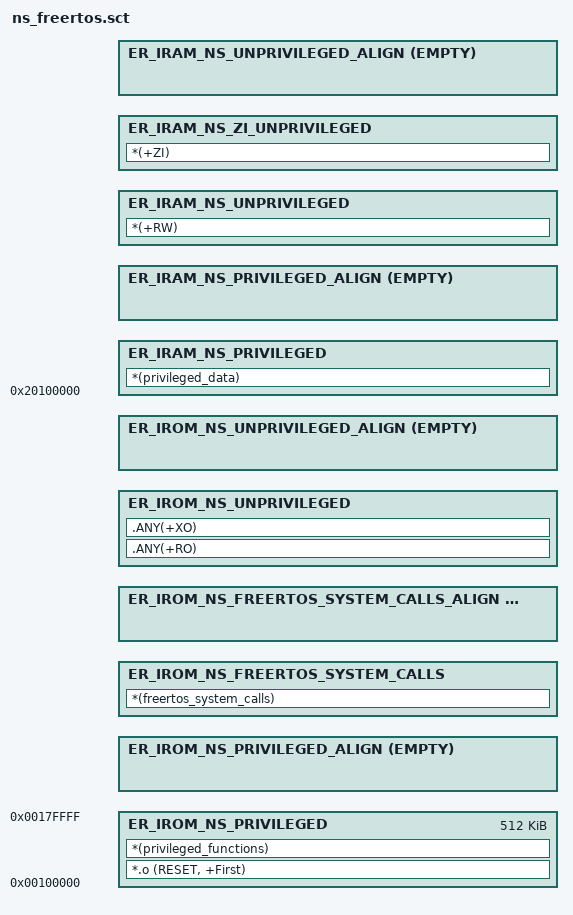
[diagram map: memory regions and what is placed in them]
#! armclang -E --target=arm-arm-none-eabi -mcpu=cortex-m33 -xc
; command above MUST be in first line (no comment above!)

/*
;-------- <<< Use Configuration Wizard in Context Menu >>> -------------------
*/

/*--------------------- Flash Configuration ----------------------------------
; <h> Flash Configuration
;   <o0> Flash Base Address <0x0-0xFFFFFFFF:8>
;   <o1> Flash Size (in Bytes) <0x0-0xFFFFFFFF:8>
; </h>
 *----------------------------------------------------------------------------*/
#define __ROM_BASE     0x00100000
#define __ROM_SIZE     0x00080000

/*--------------------- Embedded RAM Configuration ---------------------------
; <h> RAM Configuration
;   <o0> RAM Base Address    <0x0-0xFFFFFFFF:8>
;   <o1> RAM Size (in Bytes) <0x0-0xFFFFFFFF:8>
; </h>
 *----------------------------------------------------------------------------*/
#define __RAM_BASE     0x20100000
#define __RAM_SIZE     0x00040000

#define __RAM1_BASE     0x20100000
#define __RAM1_SIZE     (0x00040000 - 0x00020000)
#define __RAM2_BASE     (0x20100000 + 0x00020000)
#define __RAM2_SIZE     0x00020000

/*----------------------------------------------------------------------------
  Scatter File Definitions definition
 *----------------------------------------------------------------------------*/
#define __RO_BASE         __ROM_BASE
#define __RO_SIZE         __ROM_SIZE

#define __RW_BASE         __RAM_BASE
#define __RW_SIZE        (__RAM_SIZE - __STACK_SIZE - __HEAP_SIZE)

#define __RW1_BASE         __RAM_BASE
#define __RW1_SIZE        (__RAM_SIZE - 0x00020000)

#define __RW2_BASE        (__RAM_BASE + 0x00020000)
#define __RW2_SIZE        (__RAM_SIZE - 0x00020000 - __STACK_SIZE - __HEAP_SIZE)


LR_ROM __RO_BASE __RO_SIZE  {                       ; load region size_region
	ER_IROM_NS_PRIVILEGED __RO_BASE __RO_SIZE  
	{                                               ; load address = execution address
		*.o (RESET, +First)
		*(privileged_functions)
	}

	ER_IROM_NS_PRIVILEGED_ALIGN +0 ALIGN 32 EMPTY 0x0
	{
	}

	ER_IROM_NS_FREERTOS_SYSTEM_CALLS +0 ALIGN 32
	{
		*(freertos_system_calls)
	}

	ER_IROM_NS_FREERTOS_SYSTEM_CALLS_ALIGN +0 ALIGN 32 EMPTY 0x0
	{
	}

	ER_IROM_NS_UNPRIVILEGED +0 ALIGN 32
	{
		.ANY(+RO)
		.ANY(+XO)
	}

	ER_IROM_NS_UNPRIVILEGED_ALIGN +0 ALIGN 32 EMPTY 0x0
	{
	}

    /* rw data/ zi data*/	
	ER_IRAM_NS_PRIVILEGED  __RAM_BASE ALIGN 32
	{
		*(privileged_data)
	}

	ER_IRAM_NS_PRIVILEGED_ALIGN +0 ALIGN 32 EMPTY 0x0
	{
	}

	ER_IRAM_NS_UNPRIVILEGED +0 ALIGN 32
	{
		*(+RW)
	}

	ER_IRAM_NS_ZI_UNPRIVILEGED +0 ALIGN 32
	{
		*(+ZI)
	}

	ER_IRAM_NS_UNPRIVILEGED_ALIGN +0 ALIGN 32 EMPTY 0x0
	{
	}
}
